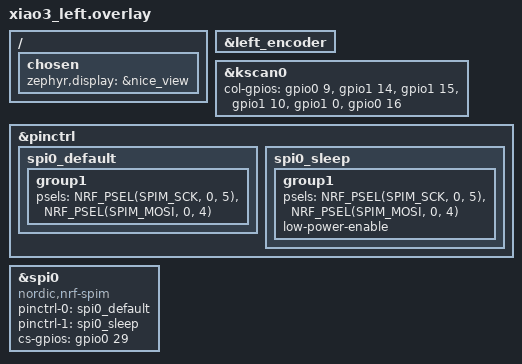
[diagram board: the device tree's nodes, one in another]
#include "xiao3.dtsi" 

&left_encoder {
	status = "okay";
};

&kscan0 {
    col-gpios               // Col1-7 0.09 1.14 1.15 1.10 1.00 0.16 0.29**
        = <&gpio0 9 GPIO_ACTIVE_HIGH> 
        , <&gpio1 14 GPIO_ACTIVE_HIGH>
        , <&gpio1 15 GPIO_ACTIVE_HIGH>
        , <&gpio1 10 GPIO_ACTIVE_HIGH> 
        , <&gpio1 0 GPIO_ACTIVE_HIGH> 
        , <&gpio0 16 GPIO_ACTIVE_HIGH> 
//        , <&gpio0 29 GPIO_ACTIVE_HIGH> 
        ;
};

&pinctrl {
    spi0_default: spi0_default {
        group1 {
            psels = <NRF_PSEL(SPIM_SCK, 0, 5)>,
                <NRF_PSEL(SPIM_MOSI, 0, 4)>;
        };
    };
    spi0_sleep: spi0_sleep {
        group1 {
            psels = <NRF_PSEL(SPIM_SCK, 0, 5)>,
                <NRF_PSEL(SPIM_MOSI, 0, 4)>;
            low-power-enable;
        };
    };
};

nice_view_spi: &spi0 {
    compatible = "nordic,nrf-spim";
    pinctrl-0 = <&spi0_default>;
    pinctrl-1 = <&spi0_sleep>;
    pinctrl-names = "default", "sleep";
    cs-gpios = <&gpio0 29 GPIO_ACTIVE_HIGH>;
};

/ {
    chosen {
        zephyr,display = &nice_view;
    };
};
